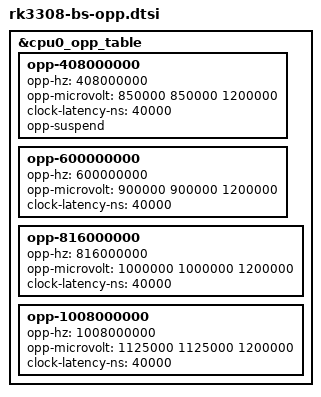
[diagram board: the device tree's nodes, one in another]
// Based on Armbian overlays-11-add-rk3308bs.patch
/dts-v1/;
/plugin/;

&cpu0_opp_table {
	opp-408000000 {
		opp-hz = /bits/ 64 <408000000>;
		opp-microvolt = <850000 850000 1200000>;
		clock-latency-ns = <40000>;
		opp-suspend;
	};
	opp-600000000 {
		opp-hz = /bits/ 64 <600000000>;
		opp-microvolt = <900000 900000 1200000>;
		clock-latency-ns = <40000>;
	};
	opp-816000000 {
		opp-hz = /bits/ 64 <816000000>;
		opp-microvolt = <1000000 1000000 1200000>;
		clock-latency-ns = <40000>;
	};
	opp-1008000000 {
		opp-hz = /bits/ 64 <1008000000>;
		opp-microvolt = <1125000 1125000 1200000>;
		clock-latency-ns = <40000>;
	};
};
